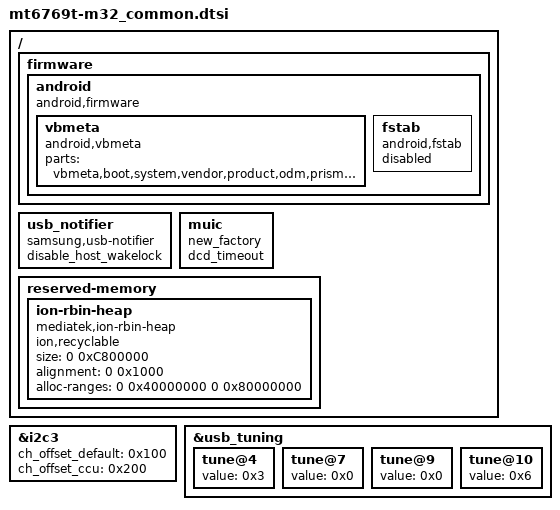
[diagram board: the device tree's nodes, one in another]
/* Generated by Samsung for MTK vendor board
 * If these files should be changed, then please make a sync with MTK
*/


#include "display_lcd_m32_common.dtsi"

/* Add Samsung configuration over here */
/ {
	fragment@model {
		target-path = "/";
		__overlay__ {
			firmware {
				android {
					compatible = "android,firmware";
					vbmeta {
						compatible = "android,vbmeta";
						parts = "vbmeta,boot,system,vendor,product,odm,prism,optics,vbmeta_system,recovery,lk,tee1";
					};
					fstab {
						compatible = "android,fstab";
						status = "disabled";
					};
				};
			};
			usb_notifier {
				compatible = "samsung,usb-notifier";
				disable_host_wakelock;
			};
			muic {
				new_factory;
				dcd_timeout;
			};
			reserved-memory {
				ion-rbin-heap {
					compatible = "mediatek,ion-rbin-heap";
					ion,recyclable;
					size = <0 0xC800000>;
					alignment = <0 0x1000>;
					alloc-ranges = <0 0x40000000 0 0x80000000>;
				};
			};			
		};
	};
};

&i2c3 {
	ch_offset_default = <0x100>;
	ch_offset_ccu = <0x200>;
};

&usb_tuning {
	/* term_vref_sel */
	tune@4 {
		value = <0x3>;
	};
	/* hstx_srctrl */
	tune@7 {
		value = <0x0>;
	};
	/* sqth */
	tune@9 {
		value = <0x0>;
	};
	/* discth */
	tune@10 {
		value = <0x6>;
	};
};
